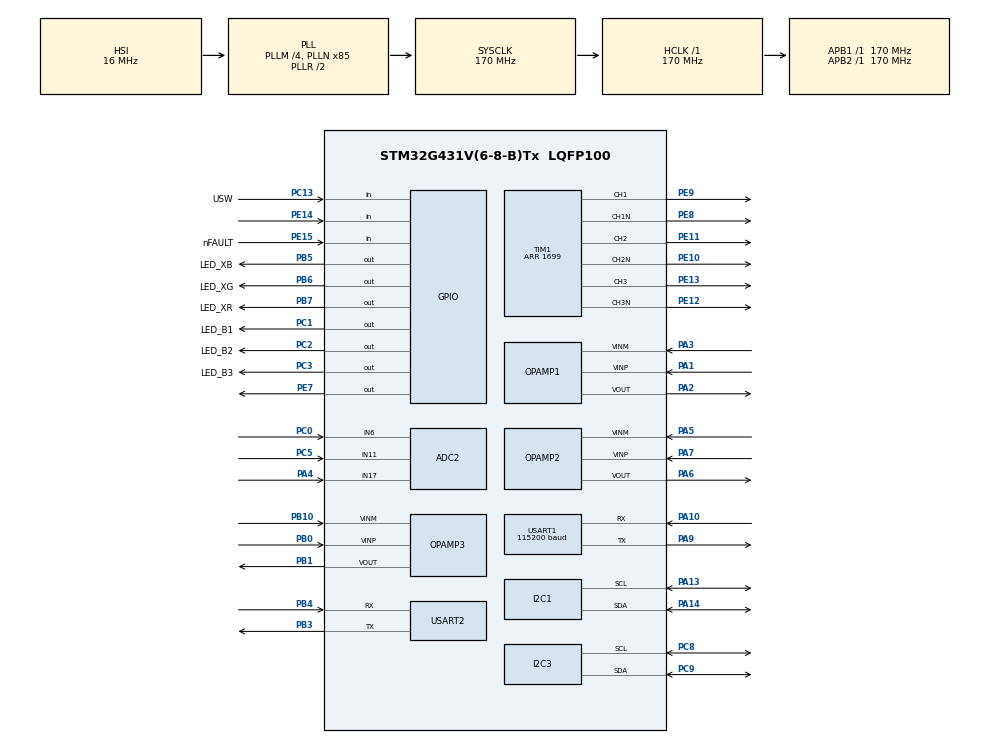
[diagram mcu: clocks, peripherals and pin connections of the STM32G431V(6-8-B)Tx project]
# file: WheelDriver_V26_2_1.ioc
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ADC1.Channel-0\#ChannelRegularConversion=ADC_CHANNEL_3
ADC1.Channel-1\#ChannelRegularConversion=ADC_CHANNEL_12
ADC1.ContinuousConvMode=ENABLE
ADC1.NbrOfConversion=2
ADC1.NbrOfConversionFlag=1
ADC1.OffsetNumber-0\#ChannelRegularConversion=ADC_OFFSET_NONE
ADC1.OffsetNumber-1\#ChannelRegularConversion=ADC_OFFSET_NONE
ADC1.Rank-0\#ChannelRegularConversion=1
ADC1.Rank-1\#ChannelRegularConversion=2
ADC1.SamplingTime-0\#ChannelRegularConversion=ADC_SAMPLETIME_2CYCLES_5
ADC1.SamplingTime-1\#ChannelRegularConversion=ADC_SAMPLETIME_2CYCLES_5
ADC1.master=1
ADC2.Channel-0\#ChannelRegularConversion=ADC_CHANNEL_3
ADC2.Channel-1\#ChannelRegularConversion=ADC_CHANNEL_17
ADC2.Channel-2\#ChannelRegularConversion=ADC_CHANNEL_6
ADC2.Channel-3\#ChannelRegularConversion=ADC_CHANNEL_11
ADC2.ContinuousConvMode=ENABLE
ADC2.DMAContinuousRequests=DISABLE
ADC2.NbrOfConversion=4
ADC2.NbrOfConversionFlag=1
ADC2.OffsetNumber-0\#ChannelRegularConversion=ADC_OFFSET_NONE
ADC2.OffsetNumber-1\#ChannelRegularConversion=ADC_OFFSET_NONE
ADC2.OffsetNumber-2\#ChannelRegularConversion=ADC_OFFSET_NONE
ADC2.OffsetNumber-3\#ChannelRegularConversion=ADC_OFFSET_NONE
ADC2.Rank-0\#ChannelRegularConversion=1
ADC2.Rank-1\#ChannelRegularConversion=2
ADC2.Rank-2\#ChannelRegularConversion=3
ADC2.Rank-3\#ChannelRegularConversion=4
ADC2.SamplingTime-0\#ChannelRegularConversion=ADC_SAMPLETIME_2CYCLES_5
ADC2.SamplingTime-1\#ChannelRegularConversion=ADC_SAMPLETIME_2CYCLES_5
ADC2.SamplingTime-2\#ChannelRegularConversion=ADC_SAMPLETIME_92CYCLES_5
ADC2.SamplingTime-3\#ChannelRegularConversion=ADC_SAMPLETIME_2CYCLES_5
Dma.Request0=USART2_RX
Dma.Request1=USART2_TX
Dma.USART2_RX.0.Direction=DMA_PERIPH_TO_MEMORY
Dma.USART2_RX.0.EventEnable=DISABLE
Dma.USART2_RX.0.Instance=DMA1_Channel2
Dma.USART2_RX.0.MemDataAlignment=DMA_MDATAALIGN_BYTE
Dma.USART2_RX.0.MemInc=DMA_MINC_ENABLE
Dma.USART2_RX.0.Mode=DMA_CIRCULAR
Dma.USART2_RX.0.PeriphDataAlignment=DMA_PDATAALIGN_BYTE
Dma.USART2_RX.0.PeriphInc=DMA_PINC_DISABLE
Dma.USART2_RX.0.Polarity=HAL_DMAMUX_REQ_GEN_RISING
Dma.USART2_RX.0.Priority=DMA_PRIORITY_LOW
Dma.USART2_RX.0.RequestNumber=1
Dma.USART2_RX.0.SignalID=NONE
Dma.USART2_RX.0.SyncEnable=DISABLE
Dma.USART2_RX.0.SyncPolarity=HAL_DMAMUX_SYNC_NO_EVENT
Dma.USART2_RX.0.SyncRequestNumber=1
Dma.USART2_RX.0.SyncSignalID=NONE
Dma.USART2_TX.1.Direction=DMA_MEMORY_TO_PERIPH
Dma.USART2_TX.1.EventEnable=DISABLE
Dma.USART2_TX.1.Instance=DMA1_Channel3
Dma.USART2_TX.1.MemDataAlignment=DMA_MDATAALIGN_BYTE
Dma.USART2_TX.1.MemInc=DMA_MINC_ENABLE
Dma.USART2_TX.1.Mode=DMA_CIRCULAR
Dma.USART2_TX.1.PeriphDataAlignment=DMA_PDATAALIGN_BYTE
Dma.USART2_TX.1.PeriphInc=DMA_PINC_DISABLE
Dma.USART2_TX.1.Polarity=HAL_DMAMUX_REQ_GEN_RISING
Dma.USART2_TX.1.Priority=DMA_PRIORITY_LOW
Dma.USART2_TX.1.RequestNumber=1
Dma.USART2_TX.1.SignalID=NONE
Dma.USART2_TX.1.SyncEnable=DISABLE
Dma.USART2_TX.1.SyncPolarity=HAL_DMAMUX_SYNC_NO_EVENT
Dma.USART2_TX.1.SyncRequestNumber=1
Dma.USART2_TX.1.SyncSignalID=NONE
I2C1.Timing=0x40B285C2
I2C3.Timing=0x40B285C2
Mcu.Family=STM32G4
Mcu.Name=STM32G431V(6-8-B)Tx
Mcu.Package=LQFP100
NVIC.DMA1_Channel2_IRQn=true\:0\:0\:false\:false\:true\:false\:true\:true
NVIC.DMA1_Channel3_IRQn=true\:0\:0\:false\:false\:true\:false\:true\:true
NVIC.PriorityGroup=NVIC_PRIORITYGROUP_4
PA1.Mode=Standalone
PA1.Signal=OPAMP1_VINP
PA10.Mode=Asynchronous
PA10.Signal=USART1_RX
PA13.Mode=I2C
PA13.Signal=I2C1_SCL
PA14.Mode=I2C
PA14.Signal=I2C1_SDA
PA2.Signal=SharedAnalog_PA2
PA3.Mode=Standalone
PA3.Signal=OPAMP1_VINM
PA4.Mode=IN17-Single-Ended
PA4.Signal=ADC2_IN17
PA5.Mode=Standalone
PA5.Signal=OPAMP2_VINM
PA6.Signal=SharedAnalog_PA6
PA7.Mode=Standalone
PA7.Signal=OPAMP2_VINP
PA9.Mode=Asynchronous
PA9.Signal=USART1_TX
PB0.Mode=Standalone
PB0.Signal=OPAMP3_VINP
PB1.Signal=SharedAnalog_PB1
PB10.Mode=Standalone
PB10.Signal=OPAMP3_VINM
PB3.Mode=Asynchronous
PB3.Signal=USART2_TX
PB4.Mode=Asynchronous
PB4.Signal=USART2_RX
PB5.GPIO_Label=LED_XB
PB5.Signal=GPIO_Output
PB6.GPIO_Label=LED_XG
PB6.Signal=GPIO_Output
PB7.GPIO_Label=LED_XR
PB7.Signal=GPIO_Output
PC0.Mode=IN6-Single-Ended
PC0.Signal=ADC2_IN6
PC1.GPIO_Label=LED_B1
PC1.Signal=GPIO_Output
PC13.GPIO_Label=USW
PC13.Signal=GPIO_Input
PC2.GPIO_Label=LED_B2
PC2.Signal=GPIO_Output
PC3.GPIO_Label=LED_B3
PC3.Signal=GPIO_Output
PC5.Mode=IN11-Single-Ended
PC5.Signal=ADC2_IN11
PC8.Mode=I2C
PC8.Signal=I2C3_SCL
PC9.Mode=I2C
PC9.Signal=I2C3_SDA
PE10.Mode=PWM Generation2 CH2 CH2N
PE10.Signal=TIM1_CH2N
PE11.Signal=S_TIM1_CH2
PE12.Mode=PWM Generation3 CH3 CH3N
PE12.Signal=TIM1_CH3N
PE13.Signal=S_TIM1_CH3
PE14.Signal=GPIO_Input
PE15.GPIO_Label=nFAULT
PE15.Signal=GPIO_Input
PE7.Signal=GPIO_Output
PE8.Mode=PWM Generation1 CH1 CH1N
PE8.Signal=TIM1_CH1N
PE9.Signal=S_TIM1_CH1
ProjectManager.HeapSize=0x200
ProjectManager.StackSize=0x400
ProjectManager.TargetToolchain=Makefile
RCC.ADC12Freq_Value=170000000
RCC.AHBFreq_Value=170000000
RCC.APB1Freq_Value=170000000
RCC.APB1TimFreq_Value=170000000
RCC.APB2Freq_Value=170000000
RCC.APB2TimFreq_Value=170000000
RCC.CortexFreq_Value=170000000
RCC.EXTERNAL_CLOCK_VALUE=12288000
RCC.HCLKFreq_Value=170000000
RCC.HSE_VALUE=8000000
RCC.HSI48_VALUE=48000000
RCC.HSI_VALUE=16000000
RCC.LSE_VALUE=32768
RCC.PLLM=RCC_PLLM_DIV4
RCC.PLLN=85
RCC.SYSCLKFreq_VALUE=170000000
RCC.SYSCLKSource=RCC_SYSCLKSOURCE_PLLCLK
RCC.USBFreq_Value=170000000
RCC.VCOOutputFreq_Value=340000000
SH.S_TIM1_CH1.0=TIM1_CH1,PWM Generation1 CH1 CH1N
SH.S_TIM1_CH2.0=TIM1_CH2,PWM Generation2 CH2 CH2N
SH.S_TIM1_CH3.0=TIM1_CH3,PWM Generation3 CH3 CH3N
SH.SharedAnalog_PA2.0=OPAMP1_VOUT,Standalone
SH.SharedAnalog_PA2.1=ADC1_IN3,IN3-Single-Ended
SH.SharedAnalog_PA6.0=OPAMP2_VOUT,Standalone
SH.SharedAnalog_PA6.1=ADC2_IN3,IN3-Single-Ended
SH.SharedAnalog_PB1.0=OPAMP3_VOUT,Standalone
SH.SharedAnalog_PB1.1=ADC1_IN12,IN12-Single-Ended
TIM1.AutoReloadPreload=TIM_AUTORELOAD_PRELOAD_ENABLE
TIM1.Channel-PWM\ Generation1\ CH1\ CH1N=TIM_CHANNEL_1
TIM1.Channel-PWM\ Generation2\ CH2\ CH2N=TIM_CHANNEL_2
TIM1.Channel-PWM\ Generation3\ CH3\ CH3N=TIM_CHANNEL_3
TIM1.DeadTime=35
TIM1.PeriodNoDither=1699
USART1.BaudRate=115200
USART1.VirtualMode-Asynchronous=VM_ASYNC
USART2.VirtualMode-Asynchronous=VM_ASYNC
VP_SYS_VS_DBSignals.Mode=DisableDeadBatterySignals
board=custom

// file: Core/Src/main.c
/* USER CODE BEGIN Header */
/**
  ******************************************************************************
  * @file           : main.c
  * @brief          : Main program body
  ******************************************************************************
  * @attention
  *
  * Copyright (c) 2025 STMicroelectronics.
  * All rights reserved.
  *
  * This software is licensed under terms that can be found in the LICENSE file
  * in the root directory of this software component.
  * If no LICENSE file comes with this software, it is provided AS-IS.
  *
  ******************************************************************************
  */
/* USER CODE END Header */
#include "main.h"

/* USER CODE BEGIN Includes */
#include "stdio.h"
#include "app.hpp"
/* USER CODE END Includes */

ADC_HandleTypeDef hadc1;
ADC_HandleTypeDef hadc2;

I2C_HandleTypeDef hi2c1;
I2C_HandleTypeDef hi2c3;

OPAMP_HandleTypeDef hopamp1;
OPAMP_HandleTypeDef hopamp2;
OPAMP_HandleTypeDef hopamp3;

TIM_HandleTypeDef htim1;

UART_HandleTypeDef huart1;
UART_HandleTypeDef huart2;
DMA_HandleTypeDef hdma_usart2_rx;
DMA_HandleTypeDef hdma_usart2_tx;

void SystemClock_Config(void);
static void MX_GPIO_Init(void);
static void MX_DMA_Init(void);
static void MX_I2C3_Init(void);
static void MX_OPAMP1_Init(void);
static void MX_OPAMP2_Init(void);
static void MX_OPAMP3_Init(void);
static void MX_TIM1_Init(void);
static void MX_ADC1_Init(void);
static void MX_ADC2_Init(void);
static void MX_I2C1_Init(void);
static void MX_USART2_UART_Init(void);
static void MX_USART1_UART_Init(void);

/* USER CODE BEGIN 0 */

int _write(int file,char* ptr,int len){
  HAL_UART_Transmit(&huart1,(uint8_t*)ptr,len,100);
  return len;
}

/* USER CODE END 0 */

int main(void)
{

  /* MCU Configuration--------------------------------------------------------*/

  /* Reset of all peripherals, Initializes the Flash interface and the Systick. */
  HAL_Init();

  /* Configure the system clock */
  SystemClock_Config();

  /* Initialize all configured peripherals */
  MX_GPIO_Init();
  MX_DMA_Init();
  MX_I2C3_Init();
  MX_OPAMP1_Init();
  MX_OPAMP2_Init();
  MX_OPAMP3_Init();
  MX_TIM1_Init();
  MX_ADC1_Init();
  MX_ADC2_Init();
  MX_I2C1_Init();
  MX_USART2_UART_Init();
  MX_USART1_UART_Init();
  /* USER CODE BEGIN 2 */
  HAL_TIM_PWM_Start(&htim1, TIM_CHANNEL_1);
  HAL_TIMEx_PWMN_Start(&htim1, TIM_CHANNEL_1);
  HAL_TIM_PWM_Start(&htim1, TIM_CHANNEL_2);
  HAL_TIMEx_PWMN_Start(&htim1, TIM_CHANNEL_2);
  HAL_TIM_PWM_Start(&htim1, TIM_CHANNEL_3);
  HAL_TIMEx_PWMN_Start(&htim1, TIM_CHANNEL_3);

  Setup();
  /* USER CODE END 2 */

  /* Infinite loop */
  /* USER CODE BEGIN WHILE */
  while (1)
  {
    MainLoop();
    /* USER CODE END WHILE */

  }
}

void SystemClock_Config(void)
{
  RCC_OscInitTypeDef RCC_OscInitStruct = {0};
  RCC_ClkInitTypeDef RCC_ClkInitStruct = {0};

  /** Configure the main internal regulator output voltage
  */
  HAL_PWREx_ControlVoltageScaling(PWR_REGULATOR_VOLTAGE_SCALE1_BOOST);

  /** Initializes the RCC Oscillators according to the specified parameters
  * in the RCC_OscInitTypeDef structure.
  */
  RCC_OscInitStruct.OscillatorType = RCC_OSCILLATORTYPE_HSI;
  RCC_OscInitStruct.HSIState = RCC_HSI_ON;
  RCC_OscInitStruct.HSICalibrationValue = RCC_HSICALIBRATION_DEFAULT;
  RCC_OscInitStruct.PLL.PLLState = RCC_PLL_ON;
  RCC_OscInitStruct.PLL.PLLSource = RCC_PLLSOURCE_HSI;
  RCC_OscInitStruct.PLL.PLLM = RCC_PLLM_DIV4;
  RCC_OscInitStruct.PLL.PLLN = 85;
  RCC_OscInitStruct.PLL.PLLP = RCC_PLLP_DIV2;
  RCC_OscInitStruct.PLL.PLLQ = RCC_PLLQ_DIV2;
  RCC_OscInitStruct.PLL.PLLR = RCC_PLLR_DIV2;
  if (HAL_RCC_OscConfig(&RCC_OscInitStruct) != HAL_OK)
  {
    Error_Handler();
  }

  /** Initializes the CPU, AHB and APB buses clocks
  */
  RCC_ClkInitStruct.ClockType = RCC_CLOCKTYPE_HCLK|RCC_CLOCKTYPE_SYSCLK
                              |RCC_CLOCKTYPE_PCLK1|RCC_CLOCKTYPE_PCLK2;
  RCC_ClkInitStruct.SYSCLKSource = RCC_SYSCLKSOURCE_PLLCLK;
  RCC_ClkInitStruct.AHBCLKDivider = RCC_SYSCLK_DIV1;
  RCC_ClkInitStruct.APB1CLKDivider = RCC_HCLK_DIV1;
  RCC_ClkInitStruct.APB2CLKDivider = RCC_HCLK_DIV1;

  if (HAL_RCC_ClockConfig(&RCC_ClkInitStruct, FLASH_LATENCY_4) != HAL_OK)
  {
    Error_Handler();
  }
}

static void MX_ADC1_Init(void)
{

  ADC_MultiModeTypeDef multimode = {0};
  ADC_ChannelConfTypeDef sConfig = {0};

  /** Common config
  */
  hadc1.Instance = ADC1;
  hadc1.Init.ClockPrescaler = ADC_CLOCK_SYNC_PCLK_DIV4;
  hadc1.Init.Resolution = ADC_RESOLUTION_12B;
  hadc1.Init.DataAlign = ADC_DATAALIGN_RIGHT;
  hadc1.Init.GainCompensation = 0;
  hadc1.Init.ScanConvMode = ADC_SCAN_ENABLE;
  hadc1.Init.EOCSelection = ADC_EOC_SINGLE_CONV;
  hadc1.Init.LowPowerAutoWait = DISABLE;
  hadc1.Init.ContinuousConvMode = ENABLE;
  hadc1.Init.NbrOfConversion = 2;
  hadc1.Init.DiscontinuousConvMode = DISABLE;
  hadc1.Init.ExternalTrigConv = ADC_SOFTWARE_START;
  hadc1.Init.ExternalTrigConvEdge = ADC_EXTERNALTRIGCONVEDGE_NONE;
  hadc1.Init.DMAContinuousRequests = DISABLE;
  hadc1.Init.Overrun = ADC_OVR_DATA_PRESERVED;
  hadc1.Init.OversamplingMode = DISABLE;
  if (HAL_ADC_Init(&hadc1) != HAL_OK)
  {
    Error_Handler();
  }

  /** Configure the ADC multi-mode
  */
  multimode.Mode = ADC_MODE_INDEPENDENT;
  if (HAL_ADCEx_MultiModeConfigChannel(&hadc1, &multimode) != HAL_OK)
  {
    Error_Handler();
  }

  /** Configure Regular Channel
  */
  sConfig.Channel = ADC_CHANNEL_3;
  sConfig.Rank = ADC_REGULAR_RANK_1;
  sConfig.SamplingTime = ADC_SAMPLETIME_2CYCLES_5;
  sConfig.SingleDiff = ADC_SINGLE_ENDED;
  sConfig.OffsetNumber = ADC_OFFSET_NONE;
  sConfig.Offset = 0;
  if (HAL_ADC_ConfigChannel(&hadc1, &sConfig) != HAL_OK)
  {
    Error_Handler();
  }

  /** Configure Regular Channel
  */
  sConfig.Channel = ADC_CHANNEL_12;
  sConfig.Rank = ADC_REGULAR_RANK_2;
  if (HAL_ADC_ConfigChannel(&hadc1, &sConfig) != HAL_OK)
  {
    Error_Handler();
  }

}

static void MX_ADC2_Init(void)
{

  ADC_ChannelConfTypeDef sConfig = {0};

  /** Common config
  */
  hadc2.Instance = ADC2;
  hadc2.Init.ClockPrescaler = ADC_CLOCK_SYNC_PCLK_DIV4;
  hadc2.Init.Resolution = ADC_RESOLUTION_12B;
  hadc2.Init.DataAlign = ADC_DATAALIGN_RIGHT;
  hadc2.Init.GainCompensation = 0;
  hadc2.Init.ScanConvMode = ADC_SCAN_DISABLE;
  hadc2.Init.EOCSelection = ADC_EOC_SINGLE_CONV;
  hadc2.Init.LowPowerAutoWait = DISABLE;
  hadc2.Init.ContinuousConvMode = DISABLE;
  hadc2.Init.NbrOfConversion = 1;
  hadc2.Init.DiscontinuousConvMode = DISABLE;
  hadc2.Init.ExternalTrigConv = ADC_SOFTWARE_START;
  hadc2.Init.ExternalTrigConvEdge = ADC_EXTERNALTRIGCONVEDGE_NONE;
  hadc2.Init.DMAContinuousRequests = DISABLE;
  hadc2.Init.Overrun = ADC_OVR_DATA_PRESERVED;
  hadc2.Init.OversamplingMode = DISABLE;
  if (HAL_ADC_Init(&hadc2) != HAL_OK)
  {
    Error_Handler();
  }

  /** Configure Regular Channel
  */
  sConfig.Channel = ADC_CHANNEL_6;
  sConfig.Rank = ADC_REGULAR_RANK_1;
  sConfig.SamplingTime = ADC_SAMPLETIME_92CYCLES_5;
  sConfig.SingleDiff = ADC_SINGLE_ENDED;
  sConfig.OffsetNumber = ADC_OFFSET_NONE;
  sConfig.Offset = 0;
  if (HAL_ADC_ConfigChannel(&hadc2, &sConfig) != HAL_OK)
  {
    Error_Handler();
  }

}

static void MX_I2C1_Init(void)
{

  hi2c1.Instance = I2C1;
  hi2c1.Init.Timing = 0x40B285C2;
  hi2c1.Init.OwnAddress1 = 0;
  hi2c1.Init.AddressingMode = I2C_ADDRESSINGMODE_7BIT;
  hi2c1.Init.DualAddressMode = I2C_DUALADDRESS_DISABLE;
  hi2c1.Init.OwnAddress2 = 0;
  hi2c1.Init.OwnAddress2Masks = I2C_OA2_NOMASK;
  hi2c1.Init.GeneralCallMode = I2C_GENERALCALL_DISABLE;
  hi2c1.Init.NoStretchMode = I2C_NOSTRETCH_DISABLE;
  if (HAL_I2C_Init(&hi2c1) != HAL_OK)
  {
    Error_Handler();
  }

  /** Configure Analogue filter
  */
  if (HAL_I2CEx_ConfigAnalogFilter(&hi2c1, I2C_ANALOGFILTER_ENABLE) != HAL_OK)
  {
    Error_Handler();
  }

  /** Configure Digital filter
  */
  if (HAL_I2CEx_ConfigDigitalFilter(&hi2c1, 0) != HAL_OK)
  {
    Error_Handler();
  }

}

static void MX_I2C3_Init(void)
{

  hi2c3.Instance = I2C3;
  hi2c3.Init.Timing = 0x40B285C2;
  hi2c3.Init.OwnAddress1 = 0;
  hi2c3.Init.AddressingMode = I2C_ADDRESSINGMODE_7BIT;
  hi2c3.Init.DualAddressMode = I2C_DUALADDRESS_DISABLE;
  hi2c3.Init.OwnAddress2 = 0;
  hi2c3.Init.OwnAddress2Masks = I2C_OA2_NOMASK;
  hi2c3.Init.GeneralCallMode = I2C_GENERALCALL_DISABLE;
  hi2c3.Init.NoStretchMode = I2C_NOSTRETCH_DISABLE;
  if (HAL_I2C_Init(&hi2c3) != HAL_OK)
  {
    Error_Handler();
  }

  /** Configure Analogue filter
  */
  if (HAL_I2CEx_ConfigAnalogFilter(&hi2c3, I2C_ANALOGFILTER_ENABLE) != HAL_OK)
  {
    Error_Handler();
  }

  /** Configure Digital filter
  */
  if (HAL_I2CEx_ConfigDigitalFilter(&hi2c3, 0) != HAL_OK)
  {
    Error_Handler();
  }

}

static void MX_OPAMP1_Init(void)
{

  hopamp1.Instance = OPAMP1;
  hopamp1.Init.PowerMode = OPAMP_POWERMODE_NORMALSPEED;
  hopamp1.Init.Mode = OPAMP_STANDALONE_MODE;
  hopamp1.Init.InvertingInput = OPAMP_INVERTINGINPUT_IO0;
  hopamp1.Init.NonInvertingInput = OPAMP_NONINVERTINGINPUT_IO0;
  hopamp1.Init.InternalOutput = DISABLE;
  hopamp1.Init.TimerControlledMuxmode = OPAMP_TIMERCONTROLLEDMUXMODE_DISABLE;
  hopamp1.Init.UserTrimming = OPAMP_TRIMMING_FACTORY;
  if (HAL_OPAMP_Init(&hopamp1) != HAL_OK)
  {
    Error_Handler();
  }

}

static void MX_OPAMP2_Init(void)
{

  hopamp2.Instance = OPAMP2;
  hopamp2.Init.PowerMode = OPAMP_POWERMODE_NORMALSPEED;
  hopamp2.Init.Mode = OPAMP_STANDALONE_MODE;
  hopamp2.Init.InvertingInput = OPAMP_INVERTINGINPUT_IO0;
  hopamp2.Init.NonInvertingInput = OPAMP_NONINVERTINGINPUT_IO0;
  hopamp2.Init.InternalOutput = DISABLE;
  hopamp2.Init.TimerControlledMuxmode = OPAMP_TIMERCONTROLLEDMUXMODE_DISABLE;
  hopamp2.Init.UserTrimming = OPAMP_TRIMMING_FACTORY;
  if (HAL_OPAMP_Init(&hopamp2) != HAL_OK)
  {
    Error_Handler();
  }

}

static void MX_OPAMP3_Init(void)
{

  hopamp3.Instance = OPAMP3;
  hopamp3.Init.PowerMode = OPAMP_POWERMODE_NORMALSPEED;
  hopamp3.Init.Mode = OPAMP_STANDALONE_MODE;
  hopamp3.Init.InvertingInput = OPAMP_INVERTINGINPUT_IO1;
  hopamp3.Init.NonInvertingInput = OPAMP_NONINVERTINGINPUT_IO0;
  hopamp3.Init.InternalOutput = DISABLE;
  hopamp3.Init.TimerControlledMuxmode = OPAMP_TIMERCONTROLLEDMUXMODE_DISABLE;
  hopamp3.Init.UserTrimming = OPAMP_TRIMMING_FACTORY;
  if (HAL_OPAMP_Init(&hopamp3) != HAL_OK)
  {
    Error_Handler();
  }

}

static void MX_TIM1_Init(void)
{

  TIM_MasterConfigTypeDef sMasterConfig = {0};
  TIM_OC_InitTypeDef sConfigOC = {0};
  TIM_BreakDeadTimeConfigTypeDef sBreakDeadTimeConfig = {0};

  htim1.Instance = TIM1;
  htim1.Init.Prescaler = 0;
  htim1.Init.CounterMode = TIM_COUNTERMODE_UP;
  htim1.Init.Period = 1699;
  htim1.Init.ClockDivision = TIM_CLOCKDIVISION_DIV1;
  htim1.Init.RepetitionCounter = 0;
  htim1.Init.AutoReloadPreload = TIM_AUTORELOAD_PRELOAD_ENABLE;
  if (HAL_TIM_PWM_Init(&htim1) != HAL_OK)
  {
    Error_Handler();
  }
  sMasterConfig.MasterOutputTrigger = TIM_TRGO_RESET;
  sMasterConfig.MasterOutputTrigger2 = TIM_TRGO2_RESET;
  sMasterConfig.MasterSlaveMode = TIM_MASTERSLAVEMODE_DISABLE;
  if (HAL_TIMEx_MasterConfigSynchronization(&htim1, &sMasterConfig) != HAL_OK)
  {
    Error_Handler();
  }
  sConfigOC.OCMode = TIM_OCMODE_PWM1;
  sConfigOC.Pulse = 0;
  sConfigOC.OCPolarity = TIM_OCPOLARITY_HIGH;
  sConfigOC.OCNPolarity = TIM_OCNPOLARITY_HIGH;
  sConfigOC.OCFastMode = TIM_OCFAST_DISABLE;
  sConfigOC.OCIdleState = TIM_OCIDLESTATE_RESET;
  sConfigOC.OCNIdleState = TIM_OCNIDLESTATE_RESET;
  if (HAL_TIM_PWM_ConfigChannel(&htim1, &sConfigOC, TIM_CHANNEL_1) != HAL_OK)
  {
    Error_Handler();
  }
  if (HAL_TIM_PWM_ConfigChannel(&htim1, &sConfigOC, TIM_CHANNEL_2) != HAL_OK)
  {
    Error_Handler();
  }
  if (HAL_TIM_PWM_ConfigChannel(&htim1, &sConfigOC, TIM_CHANNEL_3) != HAL_OK)
  {
    Error_Handler();
  }
  sBreakDeadTimeConfig.OffStateRunMode = TIM_OSSR_DISABLE;
  sBreakDeadTimeConfig.OffStateIDLEMode = TIM_OSSI_DISABLE;
  sBreakDeadTimeConfig.LockLevel = TIM_LOCKLEVEL_OFF;
  sBreakDeadTimeConfig.DeadTime = 35;
  sBreakDeadTimeConfig.BreakState = TIM_BREAK_DISABLE;
  sBreakDeadTimeConfig.BreakPolarity = TIM_BREAKPOLARITY_HIGH;
  sBreakDeadTimeConfig.BreakFilter = 0;
  sBreakDeadTimeConfig.BreakAFMode = TIM_BREAK_AFMODE_INPUT;
  sBreakDeadTimeConfig.Break2State = TIM_BREAK2_DISABLE;
  sBreakDeadTimeConfig.Break2Polarity = TIM_BREAK2POLARITY_HIGH;
  sBreakDeadTimeConfig.Break2Filter = 0;
  sBreakDeadTimeConfig.Break2AFMode = TIM_BREAK_AFMODE_INPUT;
  sBreakDeadTimeConfig.AutomaticOutput = TIM_AUTOMATICOUTPUT_DISABLE;
  if (HAL_TIMEx_ConfigBreakDeadTime(&htim1, &sBreakDeadTimeConfig) != HAL_OK)
  {
    Error_Handler();
  }
  HAL_TIM_MspPostInit(&htim1);

}

static void MX_USART1_UART_Init(void)
{

  huart1.Instance = USART1;
  huart1.Init.BaudRate = 115200;
  huart1.Init.WordLength = UART_WORDLENGTH_8B;
  huart1.Init.StopBits = UART_STOPBITS_1;
  huart1.Init.Parity = UART_PARITY_NONE;
  huart1.Init.Mode = UART_MODE_TX_RX;
  huart1.Init.HwFlowCtl = UART_HWCONTROL_NONE;
  huart1.Init.OverSampling = UART_OVERSAMPLING_16;
  huart1.Init.OneBitSampling = UART_ONE_BIT_SAMPLE_DISABLE;
  huart1.Init.ClockPrescaler = UART_PRESCALER_DIV1;
  huart1.AdvancedInit.AdvFeatureInit = UART_ADVFEATURE_NO_INIT;
  if (HAL_UART_Init(&huart1) != HAL_OK)
  {
    Error_Handler();
  }
  if (HAL_UARTEx_SetTxFifoThreshold(&huart1, UART_TXFIFO_THRESHOLD_1_8) != HAL_OK)
  {
    Error_Handler();
  }
  if (HAL_UARTEx_SetRxFifoThreshold(&huart1, UART_RXFIFO_THRESHOLD_1_8) != HAL_OK)
  {
    Error_Handler();
  }
  if (HAL_UARTEx_DisableFifoMode(&huart1) != HAL_OK)
  {
    Error_Handler();
  }

}

static void MX_USART2_UART_Init(void)
{

  huart2.Instance = USART2;
  huart2.Init.BaudRate = 115200;
  huart2.Init.WordLength = UART_WORDLENGTH_8B;
  huart2.Init.StopBits = UART_STOPBITS_1;
  huart2.Init.Parity = UART_PARITY_NONE;
  huart2.Init.Mode = UART_MODE_TX_RX;
  huart2.Init.HwFlowCtl = UART_HWCONTROL_NONE;
  huart2.Init.OverSampling = UART_OVERSAMPLING_16;
  huart2.Init.OneBitSampling = UART_ONE_BIT_SAMPLE_DISABLE;
  huart2.Init.ClockPrescaler = UART_PRESCALER_DIV1;
  huart2.AdvancedInit.AdvFeatureInit = UART_ADVFEATURE_NO_INIT;
  if (HAL_UART_Init(&huart2) != HAL_OK)
  {
    Error_Handler();
  }
  if (HAL_UARTEx_SetTxFifoThreshold(&huart2, UART_TXFIFO_THRESHOLD_1_8) != HAL_OK)
  {
    Error_Handler();
  }
  if (HAL_UARTEx_SetRxFifoThreshold(&huart2, UART_RXFIFO_THRESHOLD_1_8) != HAL_OK)
  {
    Error_Handler();
  }
  if (HAL_UARTEx_DisableFifoMode(&huart2) != HAL_OK)
  {
    Error_Handler();
  }

}

static void MX_DMA_Init(void)
{

  /* DMA controller clock enable */
  __HAL_RCC_DMAMUX1_CLK_ENABLE();
  __HAL_RCC_DMA1_CLK_ENABLE();

  /* DMA interrupt init */
  /* DMA1_Channel2_IRQn interrupt configuration */
  HAL_NVIC_SetPriority(DMA1_Channel2_IRQn, 0, 0);
  HAL_NVIC_EnableIRQ(DMA1_Channel2_IRQn);
  /* DMA1_Channel3_IRQn interrupt configuration */
  HAL_NVIC_SetPriority(DMA1_Channel3_IRQn, 0, 0);
  HAL_NVIC_EnableIRQ(DMA1_Channel3_IRQn);

}

static void MX_GPIO_Init(void)
{
  GPIO_InitTypeDef GPIO_InitStruct = {0};

  /* GPIO Ports Clock Enable */
  __HAL_RCC_GPIOC_CLK_ENABLE();
  __HAL_RCC_GPIOA_CLK_ENABLE();
  __HAL_RCC_GPIOB_CLK_ENABLE();
  __HAL_RCC_GPIOE_CLK_ENABLE();

  /*Configure GPIO pin Output Level */
  HAL_GPIO_WritePin(GPIOC, LED_B1_Pin|LED_B2_Pin|LED_B3_Pin, GPIO_PIN_RESET);

  /*Configure GPIO pin Output Level */
  HAL_GPIO_WritePin(GPIOE, GPIO_PIN_7, GPIO_PIN_RESET);

  /*Configure GPIO pin Output Level */
  HAL_GPIO_WritePin(GPIOB, LED_XB_Pin|LED_XG_Pin|LED_XR_Pin, GPIO_PIN_RESET);

  /*Configure GPIO pin : USW_Pin */
  GPIO_InitStruct.Pin = USW_Pin;
  GPIO_InitStruct.Mode = GPIO_MODE_INPUT;
  GPIO_InitStruct.Pull = GPIO_NOPULL;
  HAL_GPIO_Init(USW_GPIO_Port, &GPIO_InitStruct);

  /*Configure GPIO pins : LED_B1_Pin LED_B2_Pin LED_B3_Pin */
  GPIO_InitStruct.Pin = LED_B1_Pin|LED_B2_Pin|LED_B3_Pin;
  GPIO_InitStruct.Mode = GPIO_MODE_OUTPUT_PP;
  GPIO_InitStruct.Pull = GPIO_NOPULL;
  GPIO_InitStruct.Speed = GPIO_SPEED_FREQ_LOW;
  HAL_GPIO_Init(GPIOC, &GPIO_InitStruct);

  /*Configure GPIO pin : PE7 */
  GPIO_InitStruct.Pin = GPIO_PIN_7;
  GPIO_InitStruct.Mode = GPIO_MODE_OUTPUT_PP;
  GPIO_InitStruct.Pull = GPIO_NOPULL;
  GPIO_InitStruct.Speed = GPIO_SPEED_FREQ_LOW;
  HAL_GPIO_Init(GPIOE, &GPIO_InitStruct);

  /*Configure GPIO pins : PE14 nFAULT_Pin */
  GPIO_InitStruct.Pin = GPIO_PIN_14|nFAULT_Pin;
  GPIO_InitStruct.Mode = GPIO_MODE_INPUT;
  GPIO_InitStruct.Pull = GPIO_NOPULL;
  HAL_GPIO_Init(GPIOE, &GPIO_InitStruct);

  /*Configure GPIO pins : LED_XB_Pin LED_XG_Pin LED_XR_Pin */
  GPIO_InitStruct.Pin = LED_XB_Pin|LED_XG_Pin|LED_XR_Pin;
  GPIO_InitStruct.Mode = GPIO_MODE_OUTPUT_PP;
  GPIO_InitStruct.Pull = GPIO_NOPULL;
  GPIO_InitStruct.Speed = GPIO_SPEED_FREQ_LOW;
  HAL_GPIO_Init(GPIOB, &GPIO_InitStruct);

}

void Error_Handler(void)
{
  __disable_irq();
  while (1)
  {
  }
}
